# ESP32-S3 register map
Vendor: ESPRESSIF SYSTEMS (SHANGHAI) CO., LTD.; Series: ESP32 S-Series; File version: 22
CPU: Xtensa LX7 r0p0, little endian, no MPU, FPU, 0 interrupt priority bits
Address unit: 32 bits
Registers are 32-bit, read-write, reset 0x0 unless marked. A register's access mark holds for its fields unless they carry their own. Offsets are from the block's base; [hi:lo] are bit positions; {n}, {i} and the like mark numbered series.

## AES — AES (Advanced Encryption Standard) Accelerator
Base 0x6003A000
{0x0+4i} KEY_{i} (i=0..7) — AES key register {i}
  [31:0] KEY — Stores AES keys.
{0x20+4i} TEXT_IN_{i} (i=0..3) — Source data register {i}
  [31:0] TEXT_IN — Stores the source data when the AES accelerator operates in the Typical AES working mode.
{0x30+4i} TEXT_OUT_{i} (i=0..3) — Result data register {i}
  [31:0] TEXT_OUT — Stores the result data when the AES accelerator operates in the Typical AES working mode.
0x40 MODE — AES Mode register
  [2:0] MODE — Defines the key length and the encryption/decryption of the AES accelerator.
0x48 TRIGGER wo — AES trigger register
  [0] TRIGGER — Set this bit to 1 to start AES calculation.
0x4C STATE ro — AES state register
  [1:0] STATE — Stores the working status of the AES accelerator. For typical AES, 0: idle, 1: busy. For DMA-AES, 0: idle, 1: busy, 2: calculation_done.
{0x50+i} IV_MEM[{i}] (i=0..15) 8-bit access not given — The memory that stores initialization vector
{0x60+i} H_MEM[{i}] (i=0..15) 8-bit access not given — The memory that stores GCM hash subkey
{0x70+i} J0_MEM[{i}] (i=0..15) 8-bit access not given — The memory that stores J0
{0x80+i} T0_MEM[{i}] (i=0..15) 8-bit access not given — The memory that stores T0
0x90 DMA_ENABLE — AES accelerator working mode register
  [0] DMA_ENABLE — Defines the working mode of the AES accelerator. 1'b0: typical AES working mode, 1'b1: DMA-AES working mode.
0x94 BLOCK_MODE — AES cipher block mode register
  [2:0] BLOCK_MODE — Defines the block cipher mode of the AES accelerator operating under the DMA-AES working mode. 0x0: ECB, 0x1: CBC, 0x2: OFB, 0x3: CTR, 0x4: CFB-8, 0x5: CFB-128, 0x6: reserved, 0x7: reserved.
0x98 BLOCK_NUM — AES block number register
  [31:0] BLOCK_NUM — Stores the Block Number of plaintext or ciphertext when the AES accelerator operates under the DMA-AES working mode.
0x9C INC_SEL — Standard incrementing function configure register
  [0] INC_SEL — Defines the Standard Incrementing Function for CTR block operation. Set this bit to 0 or 1 to choose INC32 or INC128.
0xA0 AAD_BLOCK_NUM — Additional Authential Data block number register
  [31:0] AAD_BLOCK_NUM — Those bits stores the number of AAD block.
0xA4 REMAINDER_BIT_NUM — AES remainder bit number register
  [6:0] REMAINDER_BIT_NUM — Those bits stores the number of remainder bit.
0xA8 CONTINUE wo — AES continue register
  [0] CONTINUE — Set this bit to 1 to continue GCM operation.
0xAC INT_CLR wo — AES Interrupt clear register
  [0] INT_CLEAR — Set this bit to 1 to clear AES interrupt.
0xB0 INT_ENA — DMA-AES Interrupt enable register
  [0] INT_ENA — Set this bit to 1 to enable AES interrupt and 0 to disable interrupt. This field is only effective for DMA-AES operation.
0xB4 DATE reset 0x20191210 — AES version control register
  [29:0] DATE — This bits stores the version information of AES.
0xB8 DMA_EXIT wo — AES-DMA exit config
  [0] DMA_EXIT — Set this bit to 1 to exit AES operation. This field is only effective for DMA-AES operation.

## BB — BB Peripheral
Base 0x6001D000
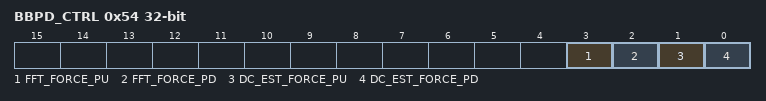
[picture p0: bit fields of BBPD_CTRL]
0x54 BBPD_CTRL — Baseband control register
  [3] FFT_FORCE_PU, [2] FFT_FORCE_PD, [1] DC_EST_FORCE_PU, [0] DC_EST_FORCE_PD

## DS — Digital Signature
Base 0x6003D000
{0x0+i} C_MEM[{i}] (i=0..1583) 8-bit access not given — Memory C
{0x630+4i} IV_{i} (i=0..3) — IV block data
  [31:0] IV — Stores IV block data
{0x800+i} X_MEM[{i}] (i=0..511) 8-bit access not given — Memory X
{0xA00+i} Z_MEM[{i}] (i=0..511) 8-bit access not given — Memory Z
0xE00 SET_START wo — Activates the DS peripheral
  [0] SET_START — Write 1 to this register to active the DS peripheral
0xE04 SET_ME wo — Starts DS operation
  [0] SET_ME — Write 1 to this register to start DS operation.
0xE08 SET_FINISH wo — Ends DS operation
  [0] SET_FINISH — Write 1 to this register to end DS operation.
0xE0C QUERY_BUSY ro — Status of the DS perihperal
  [0] QUERY_BUSY — Stores the status of the DS peripheral. 1: The DS peripheral is busy. 0: The DS peripheral is idle.
0xE10 QUERY_KEY_WRONG ro — Checks the reason why DS_KEY is not ready
  [3:0] QUERY_KEY_WRONG — 1-15: HMAC was activated, but the DS peripheral did not successfully receive the DS_KEY from the HMAC peripheral. (The biggest value is 15). 0: HMAC is not activated.
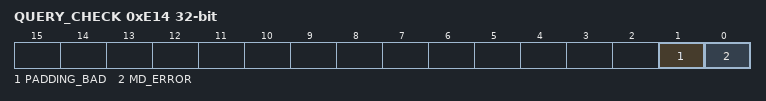
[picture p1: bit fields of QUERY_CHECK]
0xE14 QUERY_CHECK ro — Queries DS check result
  [1] PADDING_BAD — padding checkout result. 1: The padding check fails. 0: The padding check passes.
  [0] MD_ERROR — MD checkout result. 1: The MD check fails. 0: The MD check passes.
0xE20 DATE reset 0x20191217 — DS version control register
  [29:0] DATE — ds version information
